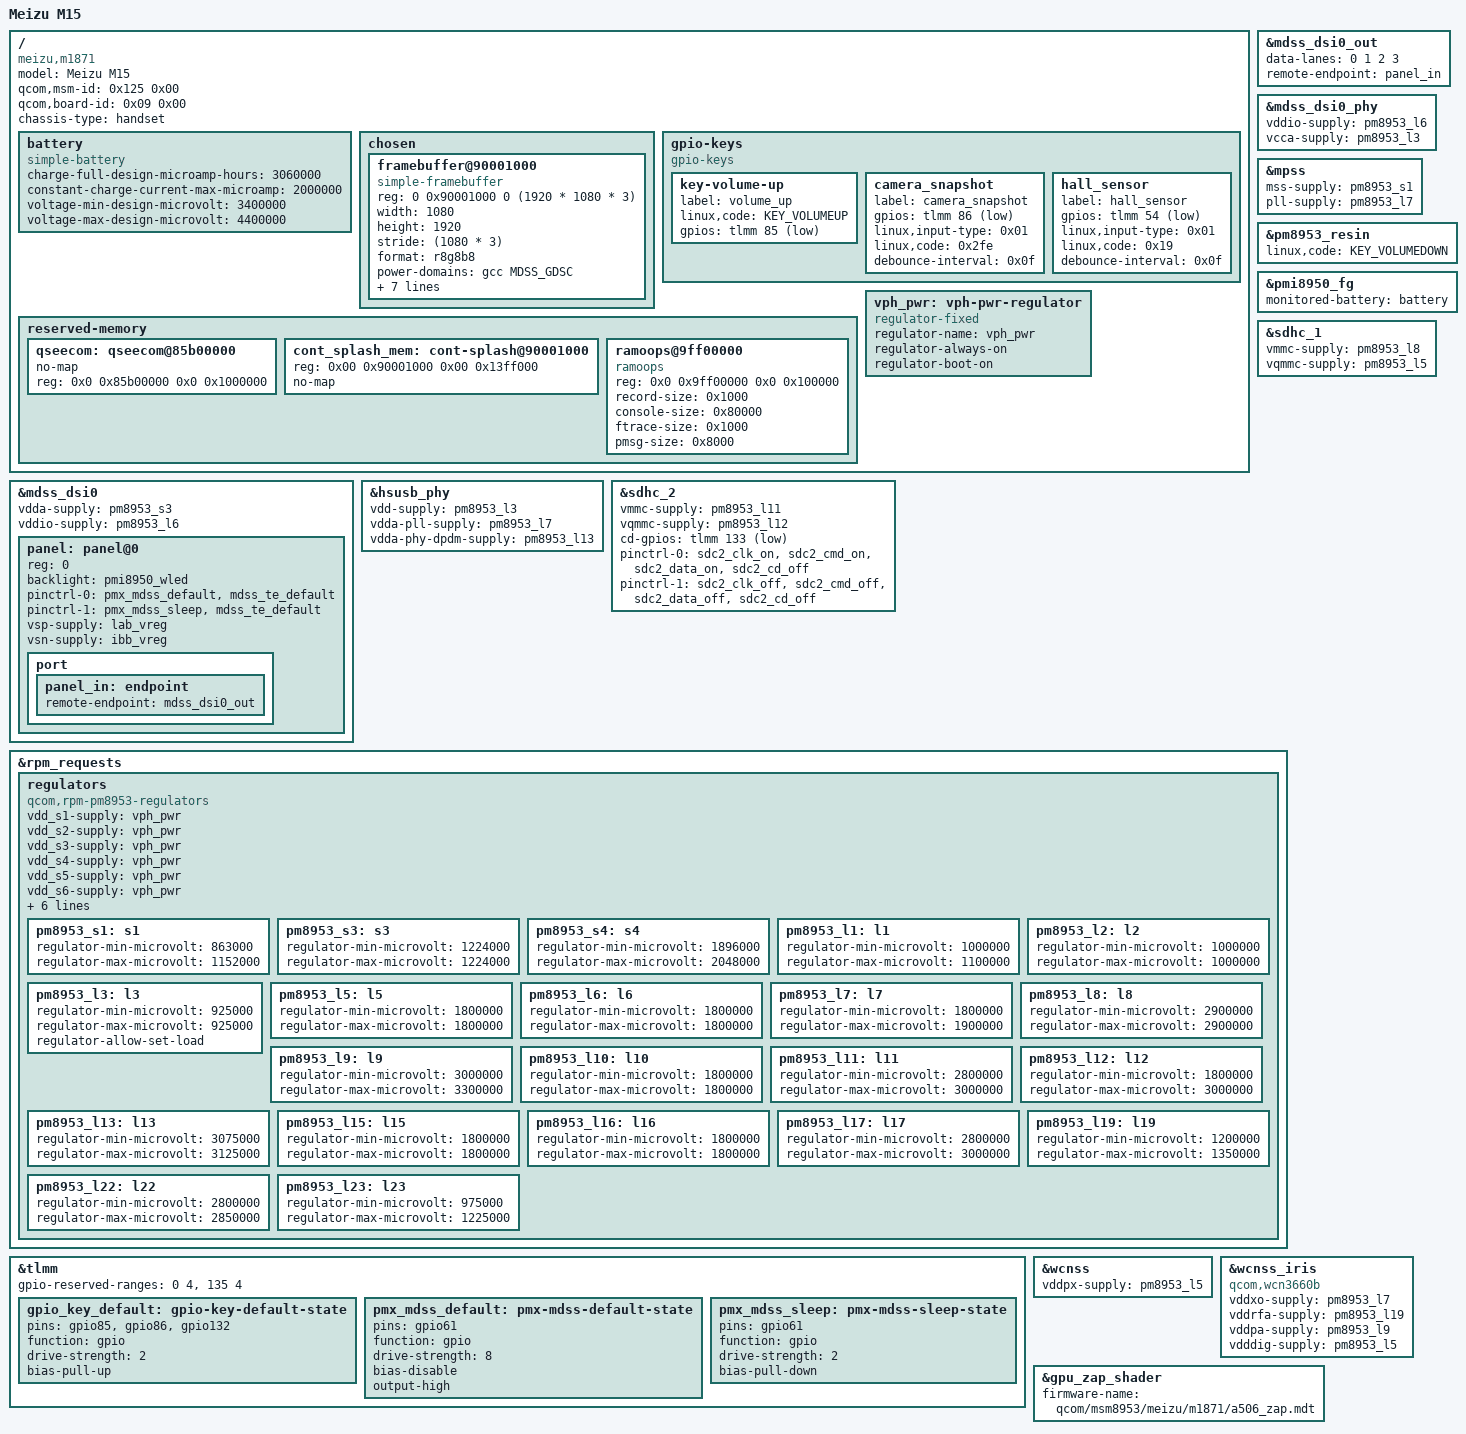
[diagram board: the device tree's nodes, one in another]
// SPDX-License-Identifier: BSD-3-Clause
/*
 * Copyright (c) 2024, Zhiyuan Bai <Bzy080408@outlook.com>
 * Copyright (c) 2024, Xinrui Li <2318678921@qq.com>
 */
/dts-v1/;

#include "msm8953.dtsi"
#include "pm8953.dtsi"
#include "pmi8950.dtsi"
#include <dt-bindings/leds/common.h>
#include "dt-bindings/pinctrl/qcom,pmic-gpio.h"


/ {
	model = "Meizu M15";
	compatible = "meizu,m1871", "qcom,msm8953";
	qcom,msm-id = <0x125 0x00>;
	qcom,board-id = <0x09 0x00>;
	chassis-type = "handset";
	
	battery: battery {
		compatible = "simple-battery";
		charge-full-design-microamp-hours = <3060000>;
		constant-charge-current-max-microamp = <2000000>;
		voltage-min-design-microvolt = <3400000>;
		voltage-max-design-microvolt = <4400000>;
	};

	chosen {
		#address-cells = <2>;
		#size-cells = <2>;
		ranges;

		framebuffer@90001000 {
			compatible = "simple-framebuffer";
			reg = <0 0x90001000 0 (1920 * 1080 * 3)>;

			width = <1080>;
			height = <1920>;
			stride = <(1080 * 3)>;
			format = "r8g8b8";

			power-domains = <&gcc MDSS_GDSC>;
			
			clocks = <&gcc GCC_MDSS_AHB_CLK>,
				 <&gcc GCC_MDSS_AXI_CLK>,
				 <&gcc GCC_MDSS_VSYNC_CLK>,
				 <&gcc GCC_MDSS_MDP_CLK>,
				 <&gcc GCC_MDSS_BYTE0_CLK>,
				 <&gcc GCC_MDSS_PCLK0_CLK>,
				 <&gcc GCC_MDSS_ESC0_CLK>;
		};
	};

	gpio-keys {
		compatible = "gpio-keys";

		key-volume-up {
			label = "volume_up";
			linux,code = <KEY_VOLUMEUP>;
			gpios = <&tlmm 85 GPIO_ACTIVE_LOW>;
		};

        camera_snapshot {
			label = "camera_snapshot";
			gpios = <&tlmm 86 GPIO_ACTIVE_LOW>;
			linux,input-type = <0x01>;
			linux,code = <0x2fe>;
			debounce-interval = <0x0f>;
		};

        hall_sensor {
			label = "hall_sensor";
			gpios = <&tlmm 54 GPIO_ACTIVE_LOW>;
			linux,input-type = <0x01>;
			linux,code = <0x19>;
			debounce-interval = <0x0f>;
		};
	};

	reserved-memory {
		qseecom: qseecom@85b00000 {
			no-map;
			reg = <0x0 0x85b00000 0x0 0x1000000>;
		};

        cont_splash_mem: cont-splash@90001000 {
			reg = <0x00 0x90001000 0x00 0x13ff000>;
			no-map;
		};

		ramoops@9ff00000 {
			compatible = "ramoops";
			reg = <0x0 0x9ff00000 0x0 0x100000>;
			record-size = <0x1000>;
			console-size = <0x80000>;
			ftrace-size = <0x1000>;
			pmsg-size = <0x8000>;
		};
	};

	vph_pwr: vph-pwr-regulator {
		compatible = "regulator-fixed";
		regulator-name = "vph_pwr";
		regulator-always-on;
		regulator-boot-on;
	};
};

&mdss_dsi0 {
	vdda-supply = <&pm8953_s3>;
	vddio-supply = <&pm8953_l6>;
	status = "okay";

	panel: panel@0 {
		reg = <0>;

		backlight = <&pmi8950_wled>;

		// reset-gpios = <&tlmm 61 GPIO_ACTIVE_LOW>;

		pinctrl-names = "default", "sleep";
		pinctrl-0 = <&pmx_mdss_default &mdss_te_default>;
		pinctrl-1 = <&pmx_mdss_sleep &mdss_te_default>;

		vsp-supply = <&lab_vreg>;
		vsn-supply = <&ibb_vreg>;

		port {
			panel_in: endpoint {
				remote-endpoint = <&mdss_dsi0_out>;
			};
		};
	};
};

&mdss_dsi0_out {
	data-lanes = <0 1 2 3>;
	remote-endpoint = <&panel_in>;
};

&mdss_dsi0_phy {
	vddio-supply = <&pm8953_l6>;
	vcca-supply = <&pm8953_l3>;

	status = "okay";
};

&mpss {
	mss-supply = <&pm8953_s1>;
	pll-supply = <&pm8953_l7>;

	status = "okay";
};

&pm8953_resin {
	linux,code = <KEY_VOLUMEDOWN>;
	status = "okay";
};

&pmi8950_fg {
	monitored-battery = <&battery>;
	status = "okay";
};

&hsusb_phy {
	vdd-supply = <&pm8953_l3>;
	vdda-pll-supply = <&pm8953_l7>;
	vdda-phy-dpdm-supply = <&pm8953_l13>;

	status = "okay";
};

&sdhc_1 {
	vmmc-supply = <&pm8953_l8>;
	vqmmc-supply = <&pm8953_l5>;

	status = "okay";
};

&sdhc_2 {
	vmmc-supply = <&pm8953_l11>;
	vqmmc-supply = <&pm8953_l12>;

	cd-gpios = <&tlmm 133 GPIO_ACTIVE_LOW>;

	pinctrl-0 = <&sdc2_clk_on &sdc2_cmd_on &sdc2_data_on &sdc2_cd_off>;
	pinctrl-1 = <&sdc2_clk_off &sdc2_cmd_off &sdc2_data_off &sdc2_cd_off>;
	pinctrl-names = "default", "sleep";

	status = "okay";
};

// &ktd2026{
//     status = "okay";
//     reg = <0x30>;

//     led@0 {
//         reg = <0>;
//         led-max-microamp = <5000>;
//         function = LED_FUNCTION_INDICATOR;
//         color = <LED_COLOR_ID_RED>;
// 	};
// };

// &aw2027_led {
//     status = "okay";
//     reg = <0x64>;

//     led@0 {
//         reg = <0>;
//         led-max-microamp = <5000>;
//         function = LED_FUNCTION_INDICATOR;
//         color = <LED_COLOR_ID_RED>;
//     };
// };

&rpm_requests {
	regulators {
		compatible = "qcom,rpm-pm8953-regulators";
		vdd_s1-supply = <&vph_pwr>;
		vdd_s2-supply = <&vph_pwr>;
		vdd_s3-supply = <&vph_pwr>;
		vdd_s4-supply = <&vph_pwr>;
		vdd_s5-supply = <&vph_pwr>;
		vdd_s6-supply = <&vph_pwr>;
		vdd_s7-supply = <&vph_pwr>;
		vdd_l1-supply = <&pm8953_s3>;
		vdd_l2_l3-supply = <&pm8953_s3>;
		vdd_l4_l5_l6_l7_l16_l19-supply = <&pm8953_s4>;
		vdd_l8_l11_l12_l13_l14_l15-supply = <&vph_pwr>;
		vdd_l9_l10_l17_l18_l22-supply = <&vph_pwr>;

		pm8953_s1: s1 {
			regulator-min-microvolt = <863000>;
			regulator-max-microvolt = <1152000>;
		};

		pm8953_s3: s3 {
			regulator-min-microvolt = <1224000>;
			regulator-max-microvolt = <1224000>;
		};

		pm8953_s4: s4 {
			regulator-min-microvolt = <1896000>;
			regulator-max-microvolt = <2048000>;
		};

		pm8953_l1: l1 {
			regulator-min-microvolt = <1000000>;
			regulator-max-microvolt = <1100000>;
		};

		pm8953_l2: l2 {
			regulator-min-microvolt = <1000000>;
			regulator-max-microvolt = <1000000>;
		};

		pm8953_l3: l3 {
			regulator-min-microvolt = <925000>;
			regulator-max-microvolt = <925000>;
			regulator-allow-set-load;
		};

		pm8953_l5: l5 {
			regulator-min-microvolt = <1800000>;
			regulator-max-microvolt = <1800000>;
		};

		pm8953_l6: l6 {
			regulator-min-microvolt = <1800000>;
			regulator-max-microvolt = <1800000>;
		};

		pm8953_l7: l7 {
			regulator-min-microvolt = <1800000>;
			regulator-max-microvolt = <1900000>;
		};

		pm8953_l8: l8 {
			regulator-min-microvolt = <2900000>;
			regulator-max-microvolt = <2900000>;
		};

		pm8953_l9: l9 {
			regulator-min-microvolt = <3000000>;
			regulator-max-microvolt = <3300000>;
		};

		pm8953_l10: l10 {
			regulator-min-microvolt = <1800000>;
			regulator-max-microvolt = <1800000>;
		};

		pm8953_l11: l11 {
			regulator-min-microvolt = <2800000>;
			regulator-max-microvolt = <3000000>;
		};

		pm8953_l12: l12 {
			regulator-min-microvolt = <1800000>;
			regulator-max-microvolt = <3000000>;
		};

		pm8953_l13: l13 {
			regulator-min-microvolt = <3075000>;
			regulator-max-microvolt = <3125000>;
		};

		pm8953_l15: l15 {
			regulator-min-microvolt = <1800000>;
			regulator-max-microvolt = <1800000>;
		};

		pm8953_l16: l16 {
			regulator-min-microvolt = <1800000>;
			regulator-max-microvolt = <1800000>;
		};

		pm8953_l17: l17 {
			regulator-min-microvolt = <2800000>;
			regulator-max-microvolt = <3000000>;
		};

		pm8953_l19: l19 {
			regulator-min-microvolt = <1200000>;
			regulator-max-microvolt = <1350000>;
		};

		pm8953_l22: l22 {
			regulator-min-microvolt = <2800000>;
			regulator-max-microvolt = <2850000>;
		};

		pm8953_l23: l23 {
			regulator-min-microvolt = <975000>;
			regulator-max-microvolt = <1225000>;
		};
	};
};

&tlmm{
	gpio-reserved-ranges = <0 4>, <135 4>;

	gpio_key_default: gpio-key-default-state {
		pins = "gpio85", "gpio86", "gpio132";
		function = "gpio";
		drive-strength = <2>;
		bias-pull-up;
	};

	pmx_mdss_default: pmx-mdss-default-state {
		pins = "gpio61";
		function = "gpio";
		drive-strength = <8>;
		bias-disable;
		output-high;
	};

	pmx_mdss_sleep: pmx-mdss-sleep-state {
		pins = "gpio61";
		function = "gpio";
		drive-strength = <2>;
		bias-pull-down;
	};
};

&wcnss {
	vddpx-supply = <&pm8953_l5>;

	status = "okay";
};

&wcnss_iris {
	compatible = "qcom,wcn3660b";

	vddxo-supply = <&pm8953_l7>;
	vddrfa-supply = <&pm8953_l19>;
	vddpa-supply = <&pm8953_l9>;
	vdddig-supply = <&pm8953_l5>;
};

&gpu_zap_shader {
	firmware-name = "qcom/msm8953/meizu/m1871/a506_zap.mdt";
};
